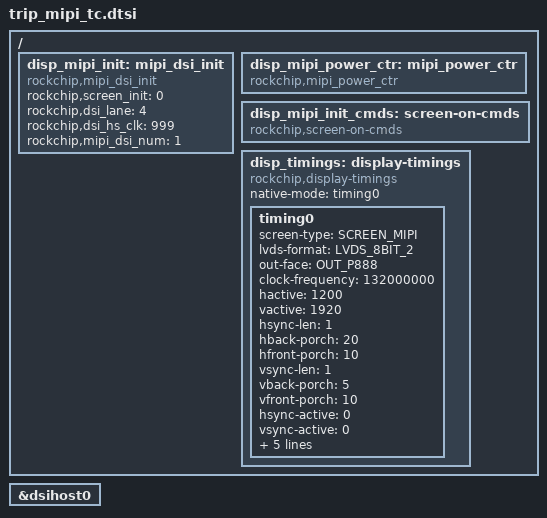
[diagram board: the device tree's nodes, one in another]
/*
 * Copyright (C) 2014 Firefly, Inc.
 * arch/arm/boot/dts/lcd-ips5k0350fpc-mipi.dtsi
 * create date: 2014-04-15
 * lcd model: ips5k0350fpc
 * resolution: 1080X1920
 * mipi channel: single 
 */

/ {	
		/* about mipi */
		disp_mipi_init: mipi_dsi_init{
					compatible = "rockchip,mipi_dsi_init";
					rockchip,screen_init	= <0>;
					rockchip,dsi_lane		= <4>;
					rockchip,dsi_hs_clk		= <999>;
					rockchip,mipi_dsi_num	= <1>;
		};

		disp_mipi_power_ctr: mipi_power_ctr {
					compatible = "rockchip,mipi_power_ctr";
		};


		disp_mipi_init_cmds: screen-on-cmds {										
					compatible = "rockchip,screen-on-cmds";				
		};

		disp_timings: display-timings {
                        native-mode = <&timing0>;
                        compatible = "rockchip,display-timings";
                        timing0: timing0 {
				screen-type = <SCREEN_MIPI>;
				//screen-type = <SCREEN_DUAL_MIPI>;
				lvds-format = <LVDS_8BIT_2>;
				out-face    = <OUT_P888>;
				//color-mode = <COLOR_RGB>;
				clock-frequency = <132000000>;
				hactive = <1200>;
				vactive = <1920>;
				hsync-len = <1>;
				hback-porch = <20>;
				hfront-porch = <10>;
				
				vsync-len = <1>;
				vback-porch = <5>;
				vfront-porch = <10>;    
				
				hsync-active = <0>;
				vsync-active = <0>;
				de-active = <0>;
				pixelclk-active = <1>;
				swap-rb = <0>;
				swap-rg = <0>;
				swap-gb = <0>;
                     	};
               };
};

&dsihost0 {
	status = "okay";
};

